# RL6955_IP_SVD register map
Vendor: Realtek
Registers are 32-bit, read-write, reset 0x0 unless marked. A register's access mark holds for its fields unless they carry their own. Offsets are from the block's base; [hi:lo] are bit positions; lines under a group give offsets from that group; {n}, {i} and the like mark numbered series; <NAME> marks a mode.

## WMAC_PAGE6
Base 0x40000000
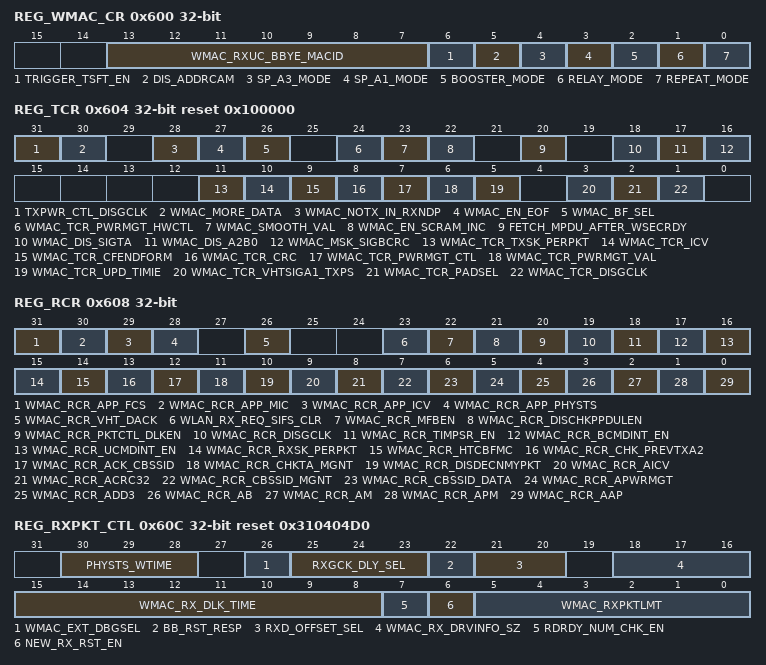
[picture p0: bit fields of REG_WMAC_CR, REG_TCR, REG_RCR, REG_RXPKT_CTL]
0x600 REG_WMAC_CR access per field
  [13:7] WMAC_RXUC_BBYE_MACID ro — when rx handshake relay byebye frame,update macid of the transmitter to this reg
  [6] TRIGGER_TSFT_EN rw — When set, enable sync tsft from trigger
  [5] DIS_ADDRCAM rw — When set,disable filtercam funciton,and use old filter
  [4] SP_A3_MODE rw — When set,enable search macid cam using rxa3. The packet will send to driver when rxa3 match and fcs ok
  [3] SP_A1_MODE rw — When set,enable search macid cam using rxa1
  [2] BOOSTER_MODE rw — When set,enable booster mode. Realy and booster are not used samtime
  [1] RELAY_MODE rw — When set,enable relay mode. Realy and booster are not used samtime
  [0] REPEAT_MODE rw — When set,enable repeat mode
0x604 REG_TCR reset 0x100000 — Transmission Configuration Register
  [31] TXPWR_CTL_DISGCLK — 1:txpwr_ctl clock gating disable 0:txpwr_ctl clock gating enable
  [30] WMAC_MORE_DATA — when set top 1, set more data bit to 1 in ACK/BA/MBA
  [28] WMAC_NOTX_IN_RXNDP — 1: block original tx when receiving NDP packet
  [27] WMAC_EN_EOF — when set to 1, enable single ampdu for qos data packet. In early mode,not set to 1.
  [26] WMAC_BF_SEL — 1: set ndp_rx_standby when rx ppdu of ndpa end; 0: set ndp_rx_standby when rx ndpa packet fcs end;
  [24] WMAC_TCR_PWRMGT_HWCTL — If this bit is set to 1, MAC will overwrite power bit of frame control according to PWR_ST. (only for RTS/CTS/ACK/CFEND/BA/BAR frames)
  [23] WMAC_SMOOTH_VAL — smooth value of plcp header HTSIG2
  [22] WMAC_EN_SCRAM_INC — Increase 1 in service field scrambler seed per tx end
  [20] FETCH_MPDU_AFTER_WSECRDY — If set to 1,mactx_mpdu_gen will fetch mpdu after wsec is ready when sectype is not tkip/wep40/wep104
  [18] WMAC_DIS_SIGTA — when set to 1, disable signaling TA information for response packet
  [17] WMAC_DIS_A2B0 — when set to 1, not check bit 0 of rx a2
  [16] WMAC_MSK_SIGBCRC — when set to 1, mask sigb crc in service field for vht packet
  [11] WMAC_TCR_TXSK_PERPKT — Search key for each mpdu
  [10] WMAC_TCR_ICV — Integrity Check Value. This bit indicates the existence of an ICV appended to an encipherment packet. 1: No ICV appended 0: ICV appended
  [9] WMAC_TCR_CFENDFORM — CF-End Frame Format.The Address 2 field of CF-End is defined to be the address of the STA contained in the AP, but in 802.11n a STA can also send CF-End.The Address 2 field is not specified clearly in this case. This register chooses between MAC ID of the STA or BSSID of the network. 0: BSSID 1: MAC ID
  [8] WMAC_TCR_CRC — Append 32-bit Cyclic Redundancy Check. This bit indicates the existence of a CRC32 appended to a packet. 1: No CRC32 appended 0: A CRC32 is appended
  [7] WMAC_TCR_PWRMGT_CTL — If this bit is set to 1, MAC will overwrite power bit of frame control according to PWR_ST. (only for data frame)
  [6] WMAC_TCR_PWRMGT_VAL — MAC will overwrite power bit of frame control according to PWR_ST.(only for data frame)
  [5] WMAC_TCR_UPD_TIMIE — when set to 1, enable hw to update beacon's time field
  [3] WMAC_TCR_VHTSIGA1_TXPS — This bit controls TXOP_PS_NOT_ALLOWED bit value of VHT-SIG-A1 field in TX VHT packets 1: TXOP_PS_NOT_ALLOWED is set to 1 0: TXOP_PS_NOT_ALLOWED is set to 0
  [2] WMAC_TCR_PADSEL — AMPDU Padding pattern selection 0: 32-bit Zero padding, 1: Zero length delimiter.
  [1] WMAC_TCR_DISGCLK — when set to 1,disable MACTX clock gating control.
0x608 REG_RCR — Receive Configuration Register
  [31] WMAC_RCR_APP_FCS — When set, wmac RX will append FCS after payload.
  [30] WMAC_RCR_APP_MIC — When this bit is set to 1, MACRX will retain the MIC at the bottom of the packet. Otherwise, MIC will be removed and reported the status in RXDESC. When a MPDU is encrypted with TKIP without MIC, MACRX will ignore this option, that is, MIC must be remained in back of the plain text.
  [29] WMAC_RCR_APP_ICV — When this bit is set to 1, MACRX will retain the ICV at the bottom of the packet. Otherwise, MIC will be removed and reported the status in RXDESC.
  [28] WMAC_RCR_APP_PHYSTS — Append RXFF0 PHY Status Enable When this bit is set, then PHY Status is appended before RX packet in RXFF. When this bit is set, the RX_DRV_INFO_SZ shall be set to include PHY Status report.
  [26] WMAC_RCR_VHT_DACK — This bit to control response type for vht single mpdu data packet. 1: ACK as response 0: BA as response
  [23] WLAN_RX_REQ_SIFS_CLR
  [22] WMAC_RCR_MFBEN — Enable immediate MCS Feedback function 1: Enable. When Rx packet with MRQ = 1"b1, then search KEYCAM to find sender"s MCS Feedback function and send response 0: Disable
  [21] WMAC_RCR_DISCHKPPDULEN — When set,do not check PPDU while the PPDU length is smaller than 14 byte.
  [20] WMAC_RCR_PKTCTL_DLKEN — When set,while rx path dead lock occurs, reset rx path
  [19] WMAC_RCR_DISGCLK — When set,disable macrx clock gating control
  [18] WMAC_RCR_TIMPSR_EN — When set, enable RX Beacon TIM Parser
  [17] WMAC_RCR_BCMDINT_EN — Broadcast data packet interrupt enable. When this bit is set, this bit is auto clear by MAC. As long as a data type broadcast packet is received, this bit will be set.
  [16] WMAC_RCR_UCMDINT_EN — Unicast data packet with FC.MD = 1 interrupt enable. When this bit is set, this bit is auto clear by MAC. As long as a data type unicast packet is received, this bit will be set.
  [15] WMAC_RCR_RXSK_PERPKT — Executing key search per MPDU
  [14] WMAC_RCR_HTCBFMC — 1: HTC -> MFC 0: MFC-> HTC
  [13] WMAC_RCR_CHK_PREVTXA2 — When set,enable check rxa1 with txa2.
  [12] WMAC_RCR_ACK_CBSSID — The field effects behavior of BA/ACK frame. 0:Only A1 match to send BA/ACK frame. 1:A1 match and satisfy BSSID condition(if BIT_CBSSID_DATA = 1) will send BA/ACK frame. If BIT_CBSSID_DATA = 0, hardware send BA/ACK frame decided by A1 match condition.
  [11] WMAC_RCR_CHKTA_MGNT — Check TransmitteBCN When set to 1, MAC will check the Transmitter Address (A2) of RX beacon or Probe response to determine if this packet belongs to this Transmitter Address (Address 2) . Both in Infrastructure mode and Ad-hoc mode.
  [10] WMAC_RCR_DISDECNMYPKT — This bit determines whether hw need to do decryption. 0: If A1 match or broadcast, do decryption. 1: Do decryption,do not check A1
  [9] WMAC_RCR_AICV — Accept Integrity Check Value Error packets. This bit determines whether packets with ICV errors will be accepted or rejected. 1: Accept 0: Reject
  [8] WMAC_RCR_ACRC32 — Accept CRC32 Error packets. When set to 1, packets with CRC32 errors will be accepted. When set to 0, packets with CRC32 errors will be rejected. 1: Accept 0: Reject
  [7] WMAC_RCR_CBSSID_MGNT — Check BSSID_BCN When set to 1, MAC will check the BSSID of RX beacon or Probe response to determine if this packet belongs to this BSSID.
  [6] WMAC_RCR_CBSSID_DATA — Check BSSID_DATA, To DS, From DS Match Packet. When set to 1, MAC will check the Rx data type frame"s BSSID, To DS, and From DS fields, to determine if it is set to Link OK in an Infrastructure or Ad hoc network. Note this setting is independent of nettype. Driver must set this bit in ad hoc mode and client mode.
  [5] WMAC_RCR_APWRMGT — Accept Power Management Packet. This bit determines whether the RTL8192D will accept or reject packets with the power management bit set. 1: Accept 0: Reject
  [4] WMAC_RCR_ADD3 — Accept Address 3 Match Packets. Set this bit to 1 to accept broadcast/multicast data type frames that Address 3 matching RTL8190"s MAC address. This bit is valid only when NETYPE (bit 3-2, MSR) is set to Link OK on an Infrastructure network.
  [3] WMAC_RCR_AB — Accept Broadcast packets. This bit determines whether broadcast packets will be accepted or rejected. 1: Accept 0: Reject
  [2] WMAC_RCR_AM — Accept Multicast packets. This bit determines whether multicast packets will be accepted or rejected. 1: Accept 0: Reject
  [1] WMAC_RCR_APM — Accept Physical Match packets. This bit determines whether physical match packets will be accepted or rejected. 1: Accept 0: Reject
  [0] WMAC_RCR_AAP — Accept Destination Address packets. This bit determines whether packets with a destination address will be accepted or rejected. 1: Accept 0: Reject
0x60C REG_RXPKT_CTL reset 0x310404D0 — RX Packet Control Register
  [30:28] PHYSTS_WTIME — wait physts timeout timer, unit 16 mac clock
  [26] WMAC_EXT_DBGSEL — enable extend dbg port sel
  [25:23] RXGCK_DLY_SEL — MAC_RX wait some time to gate clock after making the decision (about gating clock). Unit: T (MAC clock cycle) 0: 0 1: 2 2: 4 3: 8 4: 16 5: 32 6: 64 7: 128
  [22] BB_RST_RESP — When set to 1,enable bb/rdrdy_err/cca_spoofing to reset mac and will not tx response
  [21:20] RXD_OFFSET_SEL — select 2bytes of rxd to debug port 0: 0~1 bytes; 1: 2~3 bytes; 2: 4~5 bytes; 3: 6~7 bytes;
  [18:16] WMAC_RX_DRVINFO_SZ — RX DESC Driver Info Size: For RXPKTBUF layout, this field indicates the offset starting from the end of RXDESC to the beginning of RX packet. The unit is 8-byte. This value will be copied to DRV_INFO_SIZE field in RXDESC.
  [15:8] WMAC_RX_DLK_TIME — macrx dead lock timer timeout value (unit in 4us). As data_on is deasserted and no RXD is received but macrx still waits coming RXD, the deadlock timer will be enabled in this case
  [7] RDRDY_NUM_CHK_EN — When set, enable check rdrdy number is enough or not. If number is not enough will rst macrx
  [6] NEW_RX_RST_EN — when set, enable new rx rst macrx when macrx is active
  [5:0] WMAC_RXPKTLMT — RX PKT Upper Limit. The unit is 512 bytes. When "0", no RX limit is forced.
0x610 REG_MACID — MAC ID Register
  [31:0] MACID0_L — MAC Identification Number Register BIT[31:0]. Relay mode, when r_P2_WTNAP=1, as relay STA addr; r_P2_WTNAP=0, as relay STA and relay AP addr
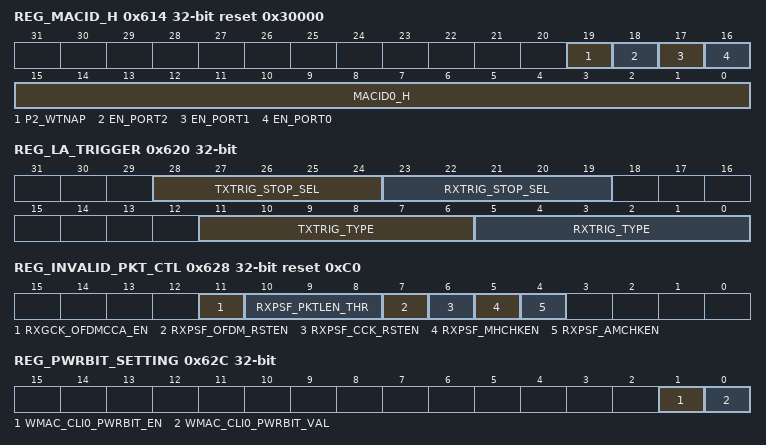
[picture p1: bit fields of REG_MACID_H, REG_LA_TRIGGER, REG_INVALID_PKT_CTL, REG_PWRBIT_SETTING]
0x614 REG_MACID_H reset 0x30000 — MAC ID Register
  [19] P2_WTNAP — when relay mode, set1,use macid2 as port2 addr; set0, use macid0 as port2 addr
  [18] EN_PORT2 — When set1,enable NAN PORT2 funtion for nan rx and response. Relay mode set 0
  [17] EN_PORT1 — When set1,enable PORT1
  [16] EN_PORT0 — When set1,enable PORT0
  [15:0] MACID0_H — MAC Identification Number Register BIT[47:32], relay mode, when r_P2_WTNAP=1, as relay STA addr; r_P2_WTNAP=0, as relay STA and relay AP addr
0x618 REG_BSSID — BSSID Register
  [31:0] BSSID0_L — Basic Station Set Identification BIT[31:0]
0x61C REG_BSSID_H — BSSID Register
  [15:0] BSSID0_H — Basic Station Set Identification BIT[47:32]
0x620 REG_LA_TRIGGER
  [28:24] TXTRIG_STOP_SEL — select tx trigger stop signal for LA dump
  [23:19] RXTRIG_STOP_SEL — select rx trigger stop signal for LA dump
  [11:6] TXTRIG_TYPE — mapping to frame control type and subtype filed, for LA trigger select
  [5:0] RXTRIG_TYPE — mapping to frame control type and subtype filed, for LA trigger select
0x624 REG_A1_ADDR_MASK reset 0xFFFFFFFF — A1 Addr Mask Register
  [31:0] WMAC_RXA1_MASK — mask rx A1 addr [39:8] for test
0x628 REG_INVALID_PKT_CTL reset 0xC0
  [11] RXGCK_OFDMCCA_EN — This bit is set to 1 to let OFDMCCA be one of the signals that can wakeup MAC from Rx_idle
  [10:8] RXPSF_PKTLEN_THR — Packet txtime threshold for invalid packet decision 3'd0: 32us 3'd1: 64us 3'd2: 128us 3'd3: 256us 3'd4: 512us 3'd5: 1024us 3'd6: 2048us 3'd7: 4096us Only the packet which txtime is longer than this threshold will trigger an invalid_pkt pulse.
  [7] RXPSF_OFDM_RSTEN — This bit is set to 1 to reset MAC Rx before sending OFDM (include OFDM, HT, VHT) packet triggered invalid_pkt pulse (0 for debug)
  [6] RXPSF_CCK_RSTEN — This bit is set to 1 to reset MAC Rx before sending CCK packet triggered invalid_pkt pulse(0 for debug)
  [5] RXPSF_MHCHKEN — 1:enable MAC to inform BB enter power saving mode as rx unmatch my MACID unicast or unmatch my BSSID Broadcast/Mutlicast mpdu
  [4] RXPSF_AMCHKEN — 1:enable MAC to inform BB enter power saving mode as rx unmatch my MACID unicast or unmatch my BSSID Broadcast/Mutlicast ampdu
0x62C REG_PWRBIT_SETTING
  [1] WMAC_CLI0_PWRBIT_EN — For client0 (port1). If this bit is set to 1, MAC will overwrite power bit of frame control according to CLI0_PWR_ST. (only for data frame)
  [0] WMAC_CLI0_PWRBIT_VAL — For client0 (port1). MAC will overwrite power bit of frame control according to CLI0_PWR_ST.(only for data frame)
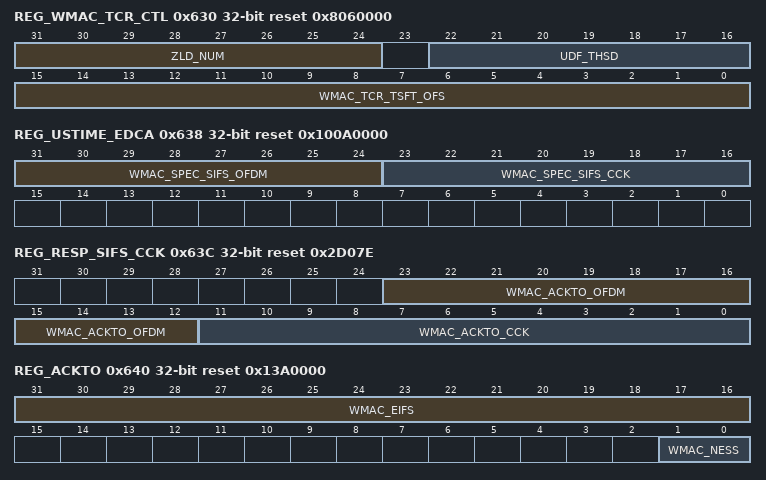
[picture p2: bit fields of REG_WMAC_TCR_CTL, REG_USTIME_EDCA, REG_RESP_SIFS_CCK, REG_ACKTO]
0x630 REG_WMAC_TCR_CTL reset 0x8060000
  [31:24] ZLD_NUM — Fetch zero length delimiter number(unit : 4bytes) when mactx underflow
  [22:16] UDF_THSD — [22]: enable underflow recovery;r_UDF_THSD[7]=0,disable underflow recovery; [21:16]: Underflow threshold
  [15:0] WMAC_TCR_TSFT_OFS — BIT_WMAC_TCR_TSFT_OFS[7:0] is for cck stamp time offset; BIT_WMAC_TCR_TSFT_OFS[15:8] is for ofdm rate time offset;
0x634 REG_STMP_THSD
  [15:8] WMAC_TCR_E_TSFT_OFS — BIT_WMAC_TCR_TSFT_OFS[7:0] is for ht/vht/he stamp time offset;
0x638 REG_USTIME_EDCA reset 0x100A0000 — US Time Tuning for EDCA Register
  [31:24] WMAC_SPEC_SIFS_OFDM — The spec SIFS value for duration calculation
  [23:16] WMAC_SPEC_SIFS_CCK — The spec SIFS value for duration calculation
0x63C REG_RESP_SIFS_CCK reset 0x2D07E — Response SIFS for CCK Register
  [23:12] WMAC_ACKTO_OFDM — This register sets the Ack time out value after Tx unicast packet with OFDM rate. It is in units of us.
  [11:0] WMAC_ACKTO_CCK — This register sets the Ack time out value after Tx unicast packet with CCK rate. It is in units of us.
0x640 REG_ACKTO reset 0x13A0000 — ACK Timeout Register
  [31:16] WMAC_EIFS — This register sets the EIFS value mentioned in 802.11 specification. It is in units of us. To receive 1Mbps ACK frame, EIFS = SIFS + 144us (preamble length) + 48us (PLCP header length) + 112us (14 bytes of data) = 314us.
  [1:0] WMAC_NESS — number of extend ht-ltf for ht ppdu
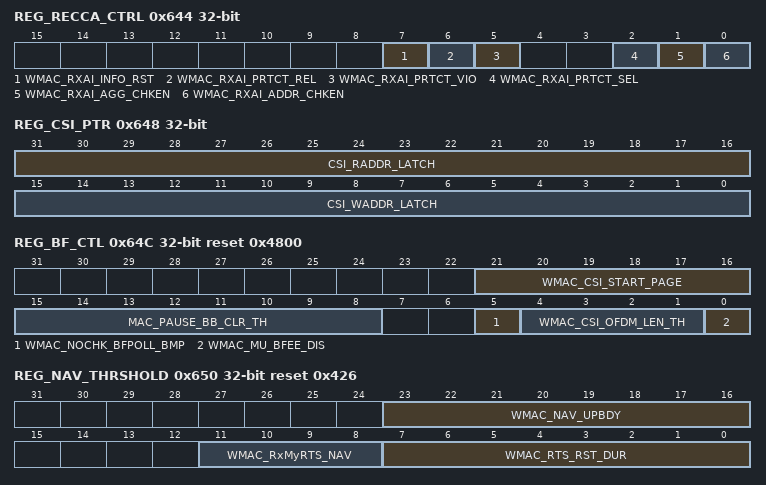
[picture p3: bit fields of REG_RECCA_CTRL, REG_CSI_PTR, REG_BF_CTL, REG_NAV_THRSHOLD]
0x644 REG_RECCA_CTRL access per field
  [7] WMAC_RXAI_INFO_RST wo — write 1 to clear bit6 and bit5 flag,one pulse
  [6] WMAC_RXAI_PRTCT_REL ro — If MAC_reset_protect is set to 0 by MAC decision circuit (address/A-MPDU checking), set this bit to 1. Reset by BIT_RXAI_INFO_RST = 1
  [5] WMAC_RXAI_PRTCT_VIO ro — If MAC gets BB_reset_MAC pulse when MAC_reset_protect = 1, set this bit to 1. Reset by BIT_RXAI_INFO_RST = 1
  [2] WMAC_RXAI_PRTCT_SEL rw — MAC_reset_protect rises at 0: DATA_ON rises 1: PLCP check OK (OFDM/CCK) or receiving 3rd/2nd (VHT/HT) RDRDY
  [1] WMAC_RXAI_AGG_CHKEN rw — This bit is only workable when BIT_RXAI_ADDR_CHKEN = 1. 1: if and only if the receiving address matched PPDU is A-MPDU and is not VHT single MPDU, then MAC inform BB not doing reCCA.
  [0] WMAC_RXAI_ADDR_CHKEN rw — This bit is set to 1 to enable MAC to inform BB not doing reCCA during receiving the address matched PPDU.
0x648 REG_CSI_PTR ro
  [31:16] CSI_RADDR_LATCH — txff read pointer latch value after Tx CSI report pkt (unit: 8B)
  [15:0] CSI_WADDR_LATCH — txff write pointer latch value at ndp_valid negative edge (unit: 8B)
0x64C REG_BF_CTL reset 0x4800
  [21:16] WMAC_CSI_START_PAGE — The starting page number of csi rpt in buffer,unit 128 byte
  [15:8] MAC_PAUSE_BB_CLR_TH — MAC_PAUSE_BB High to Low clear threshold of csidma syncff read-write pointer
  [5] WMAC_NOCHK_BFPOLL_BMP — Set this bit to ignore retransmission bitmap of rx beamforming report poll
  [4:1] WMAC_CSI_OFDM_LEN_TH — CSI frame length threshold for using legacy OFDM (unit: 128B). 0 means disabled. If CSI frame length > threshold, search from VHT or HT bitmap If CSI frame length < threshold, search from legacy OFDM bitmap
  [0] WMAC_MU_BFEE_DIS — If set to 1, HW will be SU only beamformee and not response to NDPA or Beamforming report poll.
0x650 REG_NAV_THRSHOLD reset 0x426 — NAV Threshold Register
  [23:16] WMAC_NAV_UPBDY — When NAV update is beyond this value, then NAV update is aborted. When this field is 0x00, NAV_UPPER function is disable. The unit is 128us.
  [11:8] WMAC_RxMyRTS_NAV — RX my RTS NAV. As rx my unicast RTS and RxMyRTS_NAV is not equal to zero, then rx NAV is set to wait response transition time and RxMyRTS_NAV to avoid contention with the TXOP originator. If RxMyRTS_NAV is equal to zero, this mechanism is disabled
  [7:0] WMAC_RTS_RST_DUR — RTS NAV Reset Time. This is the value in us, not including the time of CTS frame, to reset the NAV set by an RTS frame if no PHY indication occurred during this time. Refer to 802.11 1999 Section 9.2.5.4 for detailed description.
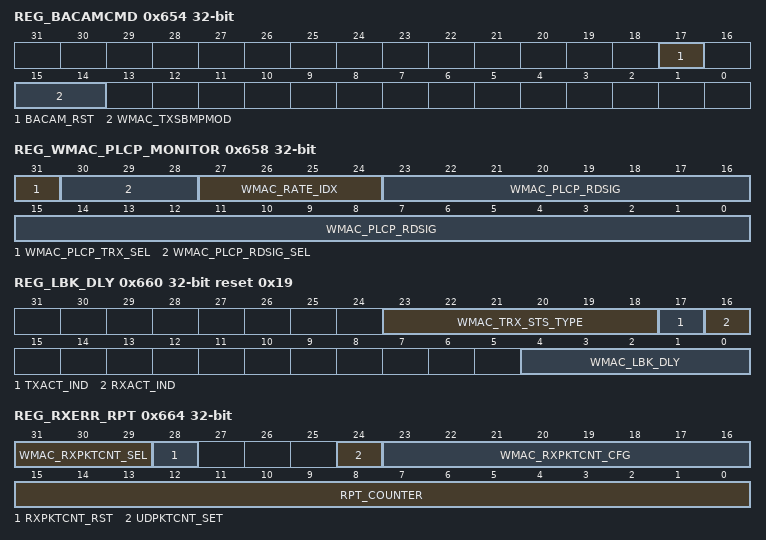
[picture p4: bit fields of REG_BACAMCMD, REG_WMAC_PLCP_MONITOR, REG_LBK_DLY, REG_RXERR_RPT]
0x654 REG_BACAMCMD access per field — Block ACK CAM Command Register
  [17] BACAM_RST wo — Set 1 to reset BA CAM. Hardware will set the invalid bit for all entries. After reset is finished this bit is reset to 0.
  [15:14] WMAC_TXSBMPMOD rw — Bit[15]: if macrx_dma idle, grant txsbmp_req Bit[14]: if macrx is idle, grant txsbmp_req 00: If FSM is idle, grant txsbmp_req 01: If FSM and mac rx is idle, grant txsbmp_req 10: If FSM and macrx_dma is idle, grant txsbmp_req 11: if FSM, macrx and macrx_dma is idle, grant txsbmp_req
0x658 REG_WMAC_PLCP_MONITOR access per field
  [31] WMAC_PLCP_TRX_SEL rw — Selection of Tx/Rx plcp header 0:Rx 1:Tx
  [30:28] WMAC_PLCP_RDSIG_SEL rw — Selection of plcp header signal field 0:LSIG 1:HTSIG1/VHTSIGA1 2:HTSIG2/VHTSIGA2 3:VHTSIGB 4: SERVICE field
  [27:24] WMAC_RATE_IDX ro — ppdu type follow trxinfo definition
  [23:0] WMAC_PLCP_RDSIG ro — Selected signal field to read out
0x660 REG_LBK_DLY access per field reset 0x19 — Loopback Delay Register
  [23:18] WMAC_TRX_STS_TYPE ro — The type and subtype field of frame control of rx packet
  [17] TXACT_IND ro — Indicate MAC/PHY is busy to tx packet
  [16] RXACT_IND ro — Indicate MAC is busy to rx packet
  [4:0] WMAC_LBK_DLY rw — Loopback Delay. In unit of 'us'; indicates the delay after which the tdrdy_mac starts. In wep/tkip mode, the delay should be larger than 15, because the initial delay of security is about 1320 cycles, approximately to 16.5 us.
0x664 REG_RXERR_RPT access per field — RX Error Report Register
  [31:29] WMAC_RXPKTCNT_SEL rw — Rx packet counter report selection RXERR_RPT_SEL[2:0]: Counter description 3'd0: counter 0 3'd1: counter 1 3'd2: counter 2 3'd3: counter 3 3'd4: counter 4 3'd5: counter 5 3'd6: counter 6 3'd7: counter 7
  [28] RXPKTCNT_RST wo — Write "1" to set the counter to zero. One pulse
  [24] UDPKTCNT_SET wo — loading user define packet counter, one pulse
  [23:16] WMAC_RXPKTCNT_CFG rw — [23:22} Select matched BSSID: 2'b0: Port 0 2'b1: Port 1 2'b2: Port 2; otherwise, do not care bssid match or not [21:18] User defined SubType [17:16] User defined Type
  [15:0] RPT_COUNTER ro — The reported counter value corresponding to Report type selected.
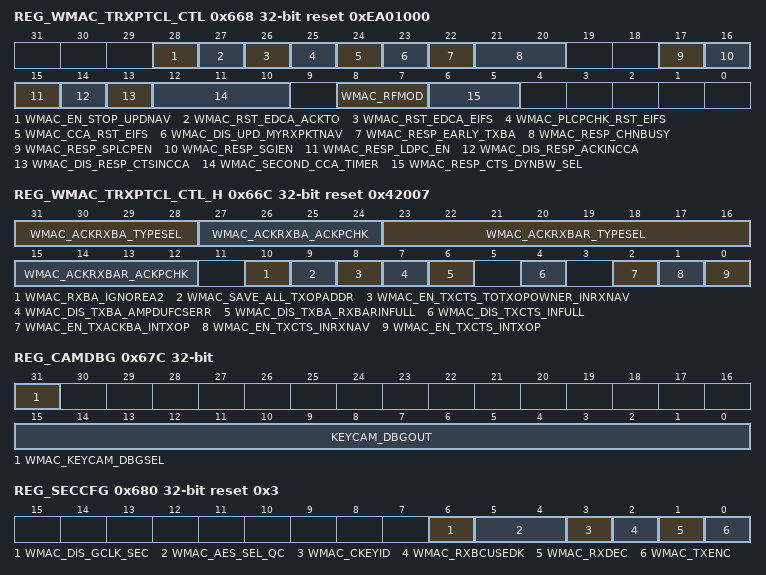
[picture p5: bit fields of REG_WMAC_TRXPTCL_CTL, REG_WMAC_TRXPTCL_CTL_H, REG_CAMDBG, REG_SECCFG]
0x668 REG_WMAC_TRXPTCL_CTL reset 0xEA01000 — WMAC TX/RX Protocol Control Register
  [28] WMAC_EN_STOP_UPDNAV — When this bit set 1. If RX packet with EDCA_REF is low, not update NAV.
  [27] WMAC_RST_EDCA_ACKTO — While in ACKTO duration, reset scheduler top to TX
  [26] WMAC_RST_EDCA_EIFS — While in EIFS duration, reset scheduler top to TX
  [25] WMAC_PLCPCHK_RST_EIFS — Reset EIFS counter while receive correct PLCP.
  [24] WMAC_CCA_RST_EIFS — Reset EIFS counter while CCA on
  [23] WMAC_DIS_UPD_MYRXPKTNAV — Do not update NAV, while receiving my packet.
  [22] WMAC_RESP_EARLY_TXBA — While phyrxon down, mac_rxactive on. Ignore mac rx busy, respond BA immediately.
  [21:20] WMAC_RESP_CHNBUSY — Define channel busy condition in responder to determine RX busy 1: PHYRXON (OFDM_VBON/CCKCCA) 0: CCA (CCKCCA/OFDMCCA)
  [17] WMAC_RESP_SPLCPEN — Enable responder send SPLCP CCK response for acknowledging Rx SPLCP CCK packet
  [16] WMAC_RESP_SGIEN — Enable responder send SGI HT-OFDM response for acknowledging Rx SGI HT-OFDM packet
  [15] WMAC_RESP_LDPC_EN — if rxpkt with ldpc, response pkt with ldpc
  [14] WMAC_DIS_RESP_ACKINCCA — Disable to response ack when cca goes high after SIFS
  [13] WMAC_DIS_RESP_CTSINCCA — 8812 Disable to response cts when cca goes high after SIFS
  [12:10] WMAC_SECOND_CCA_TIMER — 8812 The maximum time interval in us that secondary cca is pull high before primary cca When receive duplicated rts. When station response with cts, if the time that secondary cca pull high before primary cca is larger than this threshold, then secondary cca is judged to be interference, otherwise it is judged to the received RTS frame. default: 3"b0
  [8:7] WMAC_RFMOD — 8812 RF_BW indication, Used to decide response duplicated cts txsc 2"b00: 20M, 2"b01: 40M, 2"b10: 80M e.g: when RF_BW= 80M, duplicated cts BW= 40M, txsc = 9 or 10 when RF_BW = 40M, duplicated cts BW = 40M, txsc = 0
  [6:5] WMAC_RESP_CTS_DYNBW_SEL — 8812 Response cts bw selection when dynamic rts frame is received 00: current maximum bw indicated by secondary cca 01: bw fall back by one level based on bw in 2"b00 if not reach 20M 10: bw fall back by one level based on bw in 2"b01 if not reach 20M 11: bw fall back by one level based on bw in 2"b10 if not reach 20M e.g, current maximum bw indicated by secondary_cca is 80M, when set to 2"b00, the response cts bw is 80M, when set to 2"b01, cts bw is 40M, when set to 2"b10 or 2"b11 , cts bw is 20M
0x66C REG_WMAC_TRXPTCL_CTL_H reset 0x42007 — WMAC TX/RX Protocol Control Register Higher Bit
  [31:28] WMAC_ACKRXBA_TYPESEL — Determine response type for RX BA, and the definition as the bellow 0: NAV 1: Send ACK ACKBA_TYPESEL[0]: used for Basic BA ACKBA_TYPESEL[1]: used for Compression BA ACKBA_TYPESEL[2]: RSVD ACKBA_TYPESEL[3]: used for MTID BA
  [27:24] WMAC_ACKRXBA_ACKPCHK — If set 1, then check ACK Policy of BA control field to determine whether send response or not. When this bit set to 1 and a. ACK Policy of Rx BA control field is 0, then response type is controlled by ACLBA_TYPESEL. b. ACK Policy of Rx BA control field is 1, then don't send response If set 0, then ignore the ACK policy of RX BA control field and response type controlled by ACKBA_TYPESEL ACKBA_ACKPCHK[0]: used for Basic BA ACKBA_ACKPCHK[1]: used for Compression BA ACKBA_ACKPCHK[2]: RSVD ACKBA_ACKPCHK[3]: used for MTID BA
  [23:16] WMAC_ACKRXBAR_TYPESEL — Determine response type for RX BAR, and the definition as the bellow 00: NAV 01: Send BA 10: Send ACK ACKBAR_TYPESEL[1:0]: used for Basic BAR ACKBAR_TYPESEL[3:2]: used for Compression BAR ACKBAR_TYPESEL[5:4]: RSVD ACKBAR_TYPESEL[7:6]: used for MTID BAR
  [15:12] WMAC_ACKRXBAR_ACKPCHK — If set 1, then check ACK Policy of BAR control field to determine whether send response or not. When this bit set to 1 and a. ACK Policy of Rx BAR control field is 0, then response type is controlled by ACLBAR_TYPESEL. b. ACK Policy of Rx BAR control field is 1, then don't send response If set 0, then ignore the ACK policy of RX BAR control field and response type controlled by ACKBA_TYPESEL ACKBA_ACKPCHK[0]: used for Basic BAR ACKBA_ACKPCHK[1]: used for Compression BAR ACKBA_ACKPCHK[2]: RSVD ACKBA_ACKPCHK[3]: used for MTID BAR
  [10] WMAC_RXBA_IGNOREA2 — Disable check A2 field of RX BA
  [9] WMAC_SAVE_ALL_TXOPADDR
  [8] WMAC_EN_TXCTS_TOTXOPOWNER_INRXNAV — together with bit41, implement 802.11ac txop owner function
  [7] WMAC_DIS_TXBA_AMPDUFCSERR — Disable to send BA for responding RX AMPDU with FCS error subframe
  [6] WMAC_DIS_TXBA_RXBARINFULL — Disable to send BA for responding RX control wrapper BAR dropped by rxpkbuffer full
  [4] WMAC_DIS_TXCTS_INFULL — Disable to send CTS for responding RX control wrapper RTS dropped by rxpktbuffer full
  [2] WMAC_EN_TXACKBA_INTXOP — If this bit is set, then MAC will Tx ACK/BA to respond previous rx my unitcast packets send by another STA during my TXOP
  [1] WMAC_EN_TXCTS_INRXNAV — Enable to send CTS in Rx NAV
  [0] WMAC_EN_TXCTS_INTXOP — Enable to send CTS for responding RX RTS during our TXOP period
0x674 REG_TRANSMIT_ADDRSS_0 — TA0 Register
  [31:0] WMAC_TRANS_ADDR0_L — bcn and prob response transmitter address for port 0
0x678 REG_TRANSMIT_ADDRSS_0_H — TA0 Register
  [15:0] WMAC_TRANS_ADDR0_H — bcn and prob response transmitter address for port 0
0x67C REG_CAMDBG access per field — CAM Debug Register
  [31] WMAC_KEYCAM_DBGSEL rw — Select TX/RX CAM Information. Set to 1 to retrieve latest Tx search result. Set to 0 to retrieve latest Rx search result.
  [15:0] KEYCAM_DBGOUT ro — [15]:Security Key Found in CAM 0: key not found 1: key found [14:]: rx spp valid [13:11]: rx found security key type [10]: rx found security key ext_sectype [9:7]:rsvd [6:0]:Security KEY ADDR
0x680 REG_SECCFG reset 0x3 — Security Configuration Register
  [6] WMAC_DIS_GCLK_SEC — Disable gated clock control for AES/GCMP/WAPI engine.
  [5:4] WMAC_AES_SEL_QC — [12]:1: use QC[7] to compute mic; 0: not use QC[7] to compute mic [11]:1:use QC[7] to compute ctr; 0: not use QC[7] to compute ctr
  [3] WMAC_CKEYID — If this bit is set to 1, key search engine need to check if key ID matched. If this bit is set to 0, then key ID table must be filled with 2"b00.
  [2] WMAC_RXBCUSEDK — Force RX Broadcast packets Use Default Key If this bit is set to 1, use default key for RX key search when received packet is broadcast and multicast.
  [1] WMAC_RXDEC — Enable Rx Decryption Setting 1 to enable Rx hardware decryption.
  [0] WMAC_TXENC — Enable Tx Encryption Setting to 1 to enable Tx hardware encryption.
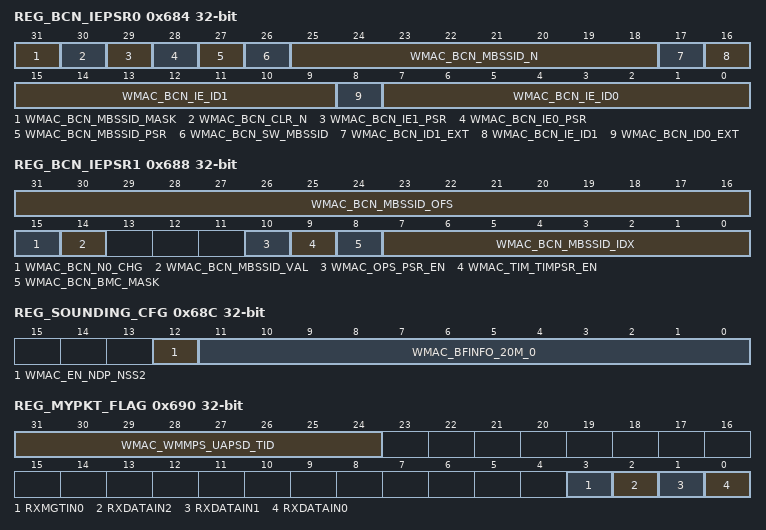
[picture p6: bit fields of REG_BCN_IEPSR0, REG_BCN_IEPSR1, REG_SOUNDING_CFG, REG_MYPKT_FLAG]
0x684 REG_BCN_IEPSR0
  [31] WMAC_BCN_MBSSID_MASK — enable tim no hit don't check whether BC/MC packets are buffered at nontransmitted BSSID
  [30] WMAC_BCN_CLR_N — enable clear macbssid indicator when no multiple BSSID element is found.
  [29] WMAC_BCN_IE1_PSR — enable parser specified ie 1 element
  [28] WMAC_BCN_IE0_PSR — enable parser specified ie0 element
  [27] WMAC_BCN_MBSSID_PSR — enable parser multiple BSSID element
  [26] WMAC_BCN_SW_MBSSID — enable the MaxBSSID indicator value from SW
  [25:18] WMAC_BCN_MBSSID_N — SW write the value of MaxBSSID Indicator field
  [17] WMAC_BCN_ID1_EXT — indicate current ie is the extend element which need to parser extend id field
  [16:9] WMAC_BCN_IE_ID1 — specified Element ID, set corresponding interrupt when it is parsed
  [8] WMAC_BCN_ID0_EXT — indicate current ie is the extend element which need to parser extend id field
  [7:0] WMAC_BCN_IE_ID0 — specified Element ID, set corresponding interrupt when it is parsed
0x688 REG_BCN_IEPSR1
  [31:16] WMAC_BCN_MBSSID_OFS — the multiple bssid element offset (byte unit) in frame body
  [15] WMAC_BCN_N0_CHG — indicate parsed maxmbssid indicator field value has changed which leads to the change of N0.
  [14] WMAC_BCN_MBSSID_VAL — indicate ofs and n0 change bit is valid.
  [10] WMAC_OPS_PSR_EN — enable parser ops frame tim elemnt and ops element
  [9] WMAC_TIM_TIMPSR_EN — enable parser tim frame tim element
  [8] WMAC_BCN_BMC_MASK — bcn tim hit bc/mc mask
  [7:0] WMAC_BCN_MBSSID_IDX — the multiple bssid index that current sta connect with
0x68C REG_SOUNDING_CFG
  [12] WMAC_EN_NDP_NSS2 — enable nss=2 when tx ndp in fpga mode
  [11:0] WMAC_BFINFO_20M_0 — beamforming info
0x690 REG_MYPKT_FLAG access per field
  [31:24] WMAC_WMMPS_UAPSD_TID rw — [7:0]:Disable interrupt 8051 when rx WMMPS UAPSD Qos data with TID7-TID0
  [3] RXMGTIN0 ro — It is set to 1 if NIC received management frame with correct BSSID and DA (including unicast and BMC).
  [2] RXDATAIN2 ro — It is set to 1 if NIC received data frame with correct BSSID and DA (including unicast and BMC).
  [1] RXDATAIN1 ro — It is set to 1 if NIC received data frame with correct BSSID and DA (including unicast and BMC).
  [0] RXDATAIN0 ro — It is set to 1 if NIC received data frame with correct BSSID and DA (including unicast and BMC).
0x694 REG_BT_ZB_COEX_TB
  [31:0] BT_ZB_COEX_TABLE — bt and zigbee coexist table
0x698 REG_NAN_BSSID_L
  [31:0] WMAC_BSSID_NAN_L — Low 32bit address for NAN BSSID. It will be used as father mac address when relay mode.
0x69C REG_NAN_BSSID_H
  [15:0] WMAC_BSSID_NAN_H — High 16bit address for NAN BSSID. It will be used as father mac address when relay mode.
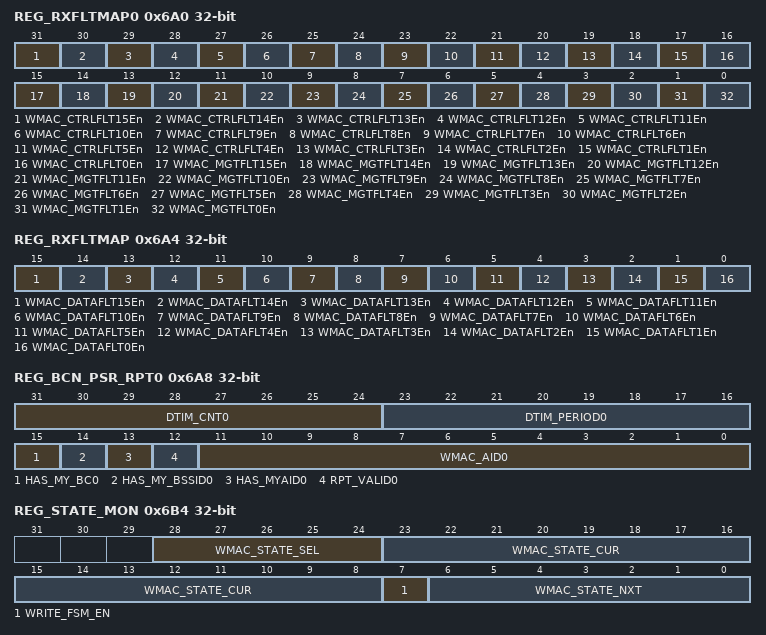
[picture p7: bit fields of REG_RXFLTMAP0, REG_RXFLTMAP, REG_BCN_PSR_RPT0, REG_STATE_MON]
0x6A0 REG_RXFLTMAP0 — RX Filter Map Group 0
  [31] WMAC_CTRLFLT15En — When set, frames with type=01 and subtype=1111 are received into RXFF.
  [30] WMAC_CTRLFLT14En — When set, frames with type=01 and subtype=1110 are received into RXFF.
  [29] WMAC_CTRLFLT13En — When set, frames with type=01 and subtype=1101 are received into RXFF.
  [28] WMAC_CTRLFLT12En — When set, frames with type=01 and subtype=1100 are received into RXFF.
  [27] WMAC_CTRLFLT11En — When set, frames with type=01 and subtype=1011 are received into RXFF.
  [26] WMAC_CTRLFLT10En — When set, frames with type=01 and subtype=1010 are received into RXFF.
  [25] WMAC_CTRLFLT9En — When set, frames with type=01 and subtype=1001 are received into RXFF.
  [24] WMAC_CTRLFLT8En — When set, frames with type=01 and subtype=1000 are received into RXFF.
  [23] WMAC_CTRLFLT7En — When set, frames with type=01 and subtype=0111 are received into RXFF.
  [22] WMAC_CTRLFLT6En — When set, frames with type=01 and subtype=0110 are received into RXFF.
  [21] WMAC_CTRLFLT5En — When set, frames with type=01 and subtype=0101 are received into RXFF.
  [20] WMAC_CTRLFLT4En — When set, frames with type=01 and subtype=0100 are received into RXFF.
  [19] WMAC_CTRLFLT3En — When set, frames with type=01 and subtype=0011 are received into RXFF.
  [18] WMAC_CTRLFLT2En — When set, frames with type=01 and subtype=0010 are received into RXFF.
  [17] WMAC_CTRLFLT1En — When set, frames with type=01 and subtype=0001 are received into RXFF.
  [16] WMAC_CTRLFLT0En — When set, frames with type=01 and subtype=0000 are received into RXFF.
  [15] WMAC_MGTFLT15En — When set, frames with type=00 and subtype=1111 are received into RXFF.
  [14] WMAC_MGTFLT14En — When set, frames with type=00 and subtype=1110 are received into RXFF.
  [13] WMAC_MGTFLT13En — When set, frames with type=00 and subtype=1101 are received into RXFF.
  [12] WMAC_MGTFLT12En — When set, frames with type=00 and subtype=1100 are received into RXFF.
  [11] WMAC_MGTFLT11En — When set, frames with type=00 and subtype=1011 are received into RXFF.
  [10] WMAC_MGTFLT10En — When set, frames with type=00 and subtype=1010 are received into RXFF.
  [9] WMAC_MGTFLT9En — When set, frames with type=00 and subtype=1001 are received into RXFF.
  [8] WMAC_MGTFLT8En — When set, frames with type=00 and subtype=1000 are received into RXFF.
  [7] WMAC_MGTFLT7En — When set, frames with type=00 and subtype=0111 are received into RXFF.
  [6] WMAC_MGTFLT6En — When set, frames with type=00 and subtype=0110 are received into RXFF.
  [5] WMAC_MGTFLT5En — When set, frames with type=00 and subtype=0101 are received into RXFF.
  [4] WMAC_MGTFLT4En — When set, frames with type=00 and subtype=0100 are received into RXFF.
  [3] WMAC_MGTFLT3En — When set, frames with type=00 and subtype=0011 are received into RXFF.
  [2] WMAC_MGTFLT2En — When set, frames with type=00 and subtype=0010 are received into RXFF.
  [1] WMAC_MGTFLT1En — When set, frames with type=00 and subtype=0001 are received into RXFF.
  [0] WMAC_MGTFLT0En — When set, frames with type=00 and subtype=0000 are received into RXFF.
0x6A4 REG_RXFLTMAP — RX Filter Map Group 1
  [15] WMAC_DATAFLT15En — When set, frames with type=10 and subtype=1111 are received into RXFF.
  [14] WMAC_DATAFLT14En — When set, frames with type=10 and subtype=1110 are received into RXFF.
  [13] WMAC_DATAFLT13En — When set, frames with type=10 and subtype=1101 are received into RXFF.
  [12] WMAC_DATAFLT12En — When set, frames with type=10 and subtype=1100 are received into RXFF.
  [11] WMAC_DATAFLT11En — When set, frames with type=10 and subtype=1011 are received into RXFF.
  [10] WMAC_DATAFLT10En — When set, frames with type=10 and subtype=1010 are received into RXFF.
  [9] WMAC_DATAFLT9En — When set, frames with type=10 and subtype=1001 are received into RXFF.
  [8] WMAC_DATAFLT8En — When set, frames with type=10 and subtype=1000 are received into RXFF.
  [7] WMAC_DATAFLT7En — When set, frames with type=10 and subtype=0111 are received into RXFF.
  [6] WMAC_DATAFLT6En — When set, frames with type=10 and subtype=0110 are received into RXFF.
  [5] WMAC_DATAFLT5En — When set, frames with type=10 and subtype=0101 are received into RXFF.
  [4] WMAC_DATAFLT4En — When set, frames with type=10 and subtype=0100 are received into RXFF.
  [3] WMAC_DATAFLT3En — When set, frames with type=10 and subtype=0011 are received into RXFF.
  [2] WMAC_DATAFLT2En — When set, frames with type=10 and subtype=0010 are received into RXFF.
  [1] WMAC_DATAFLT1En — When set, frames with type=10 and subtype=0001 are received into RXFF.
  [0] WMAC_DATAFLT0En — When set, frames with type=10 and subtype=0000 are received into RXFF.
0x6A8 REG_BCN_PSR_RPT0 — Beacon Parser Report Register
  [31:24] DTIM_CNT0 — The DTIM count field of the TIM element of Rx beacon
  [23:16] DTIM_PERIOD0 — The DTIM period field of the TIM element of Rx beacon
  [15] HAS_MY_BC0 — Indicate BC/MC packets are buffered in transmitted BSSID or AP
  [14] HAS_MY_BSSID0 — Indicate BC/MC packets are buffered in nontransmitted BSSID, SW need check crespponding dtim count field in multiple bssid index field
  [13] HAS_MYAID0 — Indicate has my unicast packet
  [12] RPT_VALID0 — when set to 1, indicate the tim report is valid
  [11:0] WMAC_AID0 — AID for MACID0
0x6AC REG_NAN_TA_L
  [31:0] WMAC_TA_NAN_L — Low 32bit address for NAN BSSID. It will be used as soft ap addr of father node when relay mode.
0x6B0 REG_NAN_TA_H
  [15:0] WMAC_TA_NAN_H — High 16bit address for NAN BSSID, It will be used as soft ap addr of father node when relay mode.
0x6B4 REG_STATE_MON access per field
  [28:24] WMAC_STATE_SEL rw — WMAC read and write FSM selection: 000,001:read mactx status 010,011:read mactx status 100:read response status 00xxx: write [6:0]to mactx fsm when [7] valid 01xxx:write [6:0]to macrx fsm when [7] valid 100xx: write [6:0]to response fsm when [7] valid
  [23:8] WMAC_STATE_CUR ro — when BIT_WRITE_FSM_EN is valid,is rsvd. When BIT_WRITE_FSM_EN is not valid, means read status
  [7] WRITE_FSM_EN wo — when set 1, generate write pulse, otherwise means read status
  [6:0] WMAC_STATE_NXT rw — when BIT_WRITE_FSM_EN is valid,Indicate the FSM current state to write.
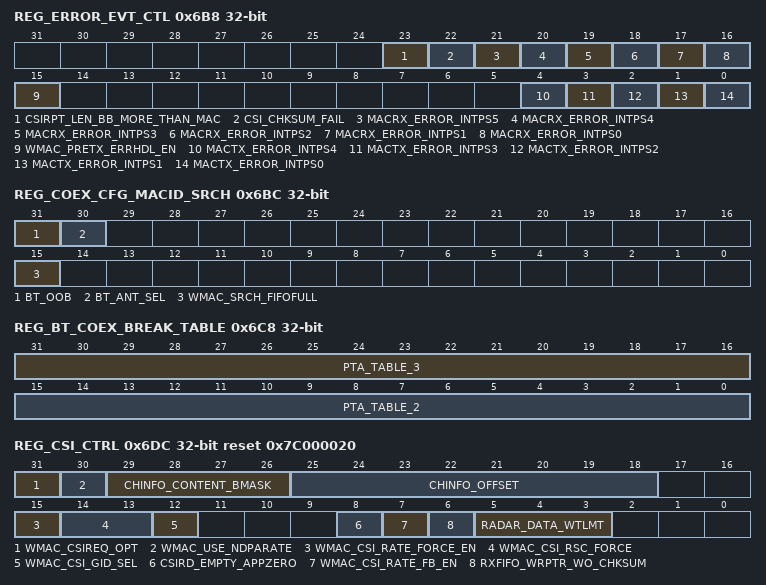
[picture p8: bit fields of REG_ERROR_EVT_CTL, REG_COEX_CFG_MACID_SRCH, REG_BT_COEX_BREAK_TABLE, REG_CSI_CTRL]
0x6B8 REG_ERROR_EVT_CTL access per field
  [23] CSIRPT_LEN_BB_MORE_THAN_MAC ro — Indicate MAC Rx csi rxd number overflow
  [22] CSI_CHKSUM_FAIL ro — Indicate MAC Rx csi rpt checksum error
  [21] MACRX_ERROR_INTPS5 ro — RSVD
  [20] MACRX_ERROR_INTPS4 ro — [20]: Indicate last MPDU length of AMPDU or PPDU length is error.
  [19] MACRX_ERROR_INTPS3 ro — [19]: Indicate rxfifo or mac phy interface fifo overflow
  [18] MACRX_ERROR_INTPS2 ro — [18]: Indicate MAC Rx occurs internal halt event
  [17] MACRX_ERROR_INTPS1 ro — [17]: Indicate Rx packet length >= 12K bytes
  [16] MACRX_ERROR_INTPS0 ro — [16]: Indicate MAC Rx occurs halt event
  [15] WMAC_PRETX_ERRHDL_EN rw — Pre tx error block enable signal
  [4] MACTX_ERROR_INTPS4 ro — RSVD
  [3] MACTX_ERROR_INTPS3 ro — [3]: Indicate PHY fetch plcp before it is ready
  [2] MACTX_ERROR_INTPS2 ro — [2]: phy_txen is set ,but wait phy_phytxon time out
  [1] MACTX_ERROR_INTPS1 ro — [1]: Indicate TXD FIFO underflow,ppdu fetch zld
  [0] MACTX_ERROR_INTPS0 ro — [0]: Indicate TXD FIFO underflow,mpdu fetch zld
0x6BC REG_COEX_CFG_MACID_SRCH
  [31] BT_OOB — out of band indication (0: in band; 1: out of band)
  [30] BT_ANT_SEL — single or dual antenna (0: single; 1: dual)
  [15] WMAC_SRCH_FIFOFULL — when set to 1, when fifofull, stop macid search;
0x6C0 REG_BT_COEX_TABLE_V1 — BT Coexistence Control register
  [31:0] PTA_TABLE_0 — coexistence table, used at dual antenna & out of band
0x6C4 REG_BT_COEX_TABLE2_V1 — BTCoexistence Control register
  [31:0] PTA_TABLE_1 — coexistence table, used at dual antenna & in band or single antenna
0x6C8 REG_BT_COEX_BREAK_TABLE — BT Coexistence Control register
  [31:16] PTA_TABLE_3 — Table used to break BT activity, when new WLAN request is coming and BT is on transmitting or receiving
  [15:0] PTA_TABLE_2 — Table used to break WLAN activity, when new BT request is coming and WLAN is on transmitting or receiving
0x6CC REG_BT_COEX_PRI_MASK — BT Coexistence Control register
  [31:0] PRI_MASK — [31]: Priority Mask for P2 NAN sync Beacon TBTT [30]: Priority Mask for P2 NAN disc Beacon TBTT [29]: Priority Mask for P2 NAN DW [28]: Priority Mask for RX Response Packet [27]: Priority Mask for RX OFDM [26]: Priority Mask for RX CCK [25:19]: Priority Mask for Tx Queue [18:11]: Priority Mask for Tx NAV [10]: Priority Mask for Tx CCK [9]: Priority Mask for Tx OFDM [8]: Priority Mask for Tx Retry Packet [7:4]: Priority Mask for Tx packet number [3]: Priority Mask for P1 TBTT [2]: Priority Mask for P0 TBTT [1]: Priority Mask for Tx response [0]: Priority Mask for Rx response
0x6D0 REG_WMAC_MU_BF_CTL
  [0] WMAC_RETXBFRPTSEQ_UPD
0x6D8 REG_RESP_TXINFO_CFG
  [31:25] WMAC_RESP_MFB — MFB information in register for response packet
0x6DC REG_CSI_CTRL reset 0x7C000020
  [31] WMAC_CSIREQ_OPT — clear csi report request if response fsm idle
  [30] WMAC_USE_NDPARATE — 1: use ndpa rx rate to decide csi report rate 0: use ndp rx rate to decide csi report rate
  [29:26] CHINFO_CONTENT_BMASK — byte mask of 4byte contents value that need to compare when set to 1, the conrresponding byte need to compare
  [25:18] CHINFO_OFFSET — used for rx normal mode the payload offset for compare with configured value. 0 meansthe 0-3 bytes payload need to compare after header/iv/eiv
  [15] WMAC_CSI_RATE_FORCE_EN — 0: disable CSI force rate. Refer to RRSR bitmask 1: CSI frame Tx rate refers to 0x6DC[29:24]
  [14:13] WMAC_CSI_RSC_FORCE — If csi_force_rate_en = 1, CSI frame sub-channel configuration 00: Primary 20Mhz BW(0x483[3:0]) 01: Follow Rx packet BW. 10: Duplicate mode. 11: Reserved
  [12] WMAC_CSI_GID_SEL — SIG-A content 1 : group id=0, 0 : group id=63
  [8] CSIRD_EMPTY_APPZERO — 0: Not append zero data when rx_fifo read csi data to empty. If csi data length of BB transmitted is smaller than MAC expected, Tx CSI report would be FCS error. 1: Append zero data when rx_fifo read csi data to empty. If csi data length of BB transmitted is smaller than MAC expected, there would be zero before FCS field of Tx CSI report pkt and the CSI report pkt would be FCS ok
  [7] WMAC_CSI_RATE_FB_EN — Enable CSI frame rate fallback (only one step in CSI RRSR) This bit is set to 1 to enable MAC to use previous latched csi resp rate for retry pkt.
  [6] RXFIFO_WRPTR_WO_CHKSUM — This bit is set to 1 when rx_fifo don't enable csi data checksum.
  [5:3] RADAR_DATA_WTLMT — Wait timeout value after data on, unit 4 mac clock cycles
0x6E0 REG_DUMMY_PAGE6
  [31:0] DUMMY
0x6E4 REG_CHINFO_CONTENT
  [31:0] CHINFO_CONTENT — the packet text value need hw to compare for channel info rx normal mode. When the content check function is enables, channel info will be reiggered only when the text match the cfg value.
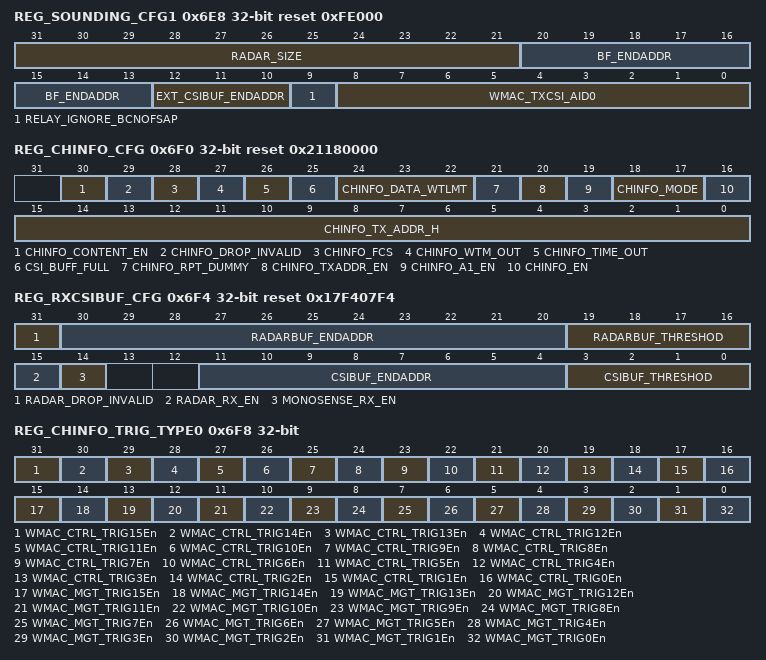
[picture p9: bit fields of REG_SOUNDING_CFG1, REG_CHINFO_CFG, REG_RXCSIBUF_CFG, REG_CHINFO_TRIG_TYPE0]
0x6E8 REG_SOUNDING_CFG1 reset 0xFE000
  [31:21] RADAR_SIZE — radar prefull window for hw to check if buffer is enough for next radar pkt
  [20:13] BF_ENDADDR — beamforming csi data occupy size of csi buffer, eco use
  [12:10] EXT_CSIBUF_ENDADDR — chinfo buffer endaddr extension. Chinfo buffer size={EXT_CSIBUF_ENDADDR, CSIBUF_ENDADDR}. Eco use
  [9] RELAY_IGNORE_BCNOFSAP — 0: update tsft when bcn a2 fit last soft ap addr 1: not update tsft when bcn a2 fit last soft ap addr, eco use
  [8:0] WMAC_TXCSI_AID0 — P_AID of the associated bemaformer0
0x6EC REG_CHINFO_ADDR
  [31:0] CHINFO_TX_ADDR_L — low 32bit tx address for trigger channel info
0x6F0 REG_CHINFO_CFG access per field reset 0x21180000
  [30] CHINFO_CONTENT_EN rw — used for rx normal mode 1: the payload( excluding mac header/iv/eiv/mic/fcs) of the specified location must match the configured value 0: do not check the payload value
  [29] CHINFO_DROP_INVALID rw — when set to 1, will drop channe info if valid bit of bb header is 0
  [28] CHINFO_FCS rw — when set to 1, will not check channel info fcs ok flag
  [27] CHINFO_WTM_OUT ro — BB does't send channel info when timeout occur
  [26] CHINFO_TIME_OUT ro — BB send channel info length is less than report length
  [25] CSI_BUFF_FULL ro — Indicate rxcsibuff full occur
  [24:22] CHINFO_DATA_WTLMT rw — Wait timeout value after repuest channe info, unit 4 mac clock cycles
  [21] CHINFO_RPT_DUMMY rw — 1:rx chinfo rpt alll segment 0: rx chinfo rpt only data
  [20] CHINFO_TXADDR_EN rw — 1: chinfo trigger condition need check a2 match txaddr or rx is cts/ack 0: not need to check a2
  [19] CHINFO_A1_EN rw — 1: chinfo trigger condition need check a1 match self mac address 0: not need to check a1
  [18:17] CHINFO_MODE rw — channel info mode setting. 0: enable normal rx trigger; 1: enable ndpa trigger; note: repsonse mode decided by tx descriptor. Valid when r_CHINFO_EN is 1.
  [16] CHINFO_EN rw — enable for getting channel info from BB. When set to 0, will not trigger channel info function
  [15:0] CHINFO_TX_ADDR_H rw — high 16bit tx address for trigger channel info
0x6F4 REG_RXCSIBUF_CFG reset 0x17F407F4
  [31] RADAR_DROP_INVALID — when set to 1, will not drop radar info if valid bit of bb header is 0
  [30:20] RADARBUF_ENDADDR — rx radarbuffer boundary, default is 3K bytes
  [19:16] RADARBUF_THRESHOD — rx radar buffer full threshold, size must greater than or equal to radar descriptors
  [15] RADAR_RX_EN — enable for getting radar rpt from BB. When set to 0, will not rx radar rpt from bb
  [14] MONOSENSE_RX_EN — enable for getting monosense from BB. When set to 0, will not rx monosense
  [11:4] CSIBUF_ENDADDR — rxcsibuffer boundary, default is 1K bytes
  [3:0] CSIBUF_THRESHOD — rxcsibuffer full threshold, size must greater than or equal to csi descriptors
0x6F8 REG_CHINFO_TRIG_TYPE0
  [31] WMAC_CTRL_TRIG15En — When set, frames with type=01 and subtype=1111 will triggerchannel info.
  [30] WMAC_CTRL_TRIG14En — When set, frames with type=01 and subtype=1110 will triggerchannel info.
  [29] WMAC_CTRL_TRIG13En — When set, frames with type=01 and subtype=1101 will triggerchannel info.
  [28] WMAC_CTRL_TRIG12En — When set, frames with type=01 and subtype=1100 will triggerchannel info.
  [27] WMAC_CTRL_TRIG11En — When set, frames with type=01 and subtype=1011 will triggerchannel info.
  [26] WMAC_CTRL_TRIG10En — When set, frames with type=01 and subtype=1010 will triggerchannel info.
  [25] WMAC_CTRL_TRIG9En — When set, frames with type=01 and subtype=1001 will triggerchannel info.
  [24] WMAC_CTRL_TRIG8En — When set, frames with type=01 and subtype=1000 will triggerchannel info.
  [23] WMAC_CTRL_TRIG7En — When set, frames with type=01 and subtype=0111 will triggerchannel info.
  [22] WMAC_CTRL_TRIG6En — When set, frames with type=01 and subtype=0110 will triggerchannel info.
  [21] WMAC_CTRL_TRIG5En — When set, frames with type=01 and subtype=0101 will triggerchannel info.
  [20] WMAC_CTRL_TRIG4En — When set, frames with type=01 and subtype=0100 will triggerchannel info.
  [19] WMAC_CTRL_TRIG3En — When set, frames with type=01 and subtype=0011 will triggerchannel info.
  [18] WMAC_CTRL_TRIG2En — When set, frames with type=01 and subtype=0010 will triggerchannel info.
  [17] WMAC_CTRL_TRIG1En — When set, frames with type=01 and subtype=0001 will triggerchannel info.
  [16] WMAC_CTRL_TRIG0En — When set, frames with type=01 and subtype=0000 will triggerchannel info.
  [15] WMAC_MGT_TRIG15En — When set, frames with type=00 and subtype=1111 will triggerchannel info.
  [14] WMAC_MGT_TRIG14En — When set, frames with type=00 and subtype=1110 will triggerchannel info.
  [13] WMAC_MGT_TRIG13En — When set, frames with type=00 and subtype=1101 will triggerchannel info.
  [12] WMAC_MGT_TRIG12En — When set, frames with type=00 and subtype=1100 will triggerchannel info.
  [11] WMAC_MGT_TRIG11En — When set, frames with type=00 and subtype=1011 will triggerchannel info.
  [10] WMAC_MGT_TRIG10En — When set, frames with type=00 and subtype=1010 will triggerchannel info.
  [9] WMAC_MGT_TRIG9En — When set, frames with type=00 and subtype=1001 will triggerchannel info.
  [8] WMAC_MGT_TRIG8En — When set, frames with type=00 and subtype=1000 will triggerchannel info.
  [7] WMAC_MGT_TRIG7En — When set, frames with type=00 and subtype=0111 will triggerchannel info.
  [6] WMAC_MGT_TRIG6En — When set, frames with type=00 and subtype=0110 will triggerchannel info.
  [5] WMAC_MGT_TRIG5En — When set, frames with type=00 and subtype=0101 will triggerchannel info.
  [4] WMAC_MGT_TRIG4En — When set, frames with type=00 and subtype=0100 will triggerchannel info.
  [3] WMAC_MGT_TRIG3En — When set, frames with type=00 and subtype=0011 will triggerchannel info.
  [2] WMAC_MGT_TRIG2En — When set, frames with type=00 and subtype=0010 will triggerchannel info.
  [1] WMAC_MGT_TRIG1En — When set, frames with type=00 and subtype=0001 will triggerchannel info.
  [0] WMAC_MGT_TRIG0En — When set, frames with type=00 and subtype=0000 will triggerchannel info.
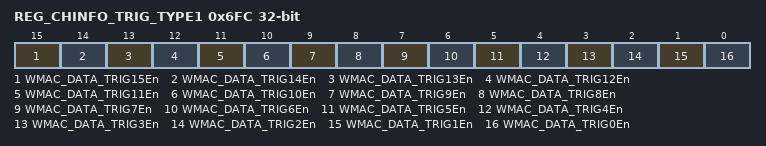
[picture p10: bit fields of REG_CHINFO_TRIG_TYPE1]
0x6FC REG_CHINFO_TRIG_TYPE1
  [15] WMAC_DATA_TRIG15En — When set, frames with type=10 and subtype=1111 will triggerchannel info.
  [14] WMAC_DATA_TRIG14En — When set, frames with type=10 and subtype=1110 will triggerchannel info.
  [13] WMAC_DATA_TRIG13En — When set, frames with type=10 and subtype=1101 will triggerchannel info.
  [12] WMAC_DATA_TRIG12En — When set, frames with type=10 and subtype=1100 will triggerchannel info.
  [11] WMAC_DATA_TRIG11En — When set, frames with type=10 and subtype=1011 will triggerchannel info.
  [10] WMAC_DATA_TRIG10En — When set, frames with type=10 and subtype=1010 will triggerchannel info.
  [9] WMAC_DATA_TRIG9En — When set, frames with type=10 and subtype=1001 will triggerchannel info.
  [8] WMAC_DATA_TRIG8En — When set, frames with type=10 and subtype=1000 will triggerchannel info.
  [7] WMAC_DATA_TRIG7En — When set, frames with type=10 and subtype=0111 will triggerchannel info.
  [6] WMAC_DATA_TRIG6En — When set, frames with type=10 and subtype=0110 will triggerchannel info.
  [5] WMAC_DATA_TRIG5En — When set, frames with type=10 and subtype=0101 will triggerchannel info.
  [4] WMAC_DATA_TRIG4En — When set, frames with type=10 and subtype=0100 will triggerchannel info.
  [3] WMAC_DATA_TRIG3En — When set, frames with type=10 and subtype=0011 will triggerchannel info.
  [2] WMAC_DATA_TRIG2En — When set, frames with type=10 and subtype=0010 will triggerchannel info.
  [1] WMAC_DATA_TRIG1En — When set, frames with type=10 and subtype=0001 will triggerchannel info.
  [0] WMAC_DATA_TRIG0En — When set, frames with type=10 and subtype=0000 will triggerchannel info.
